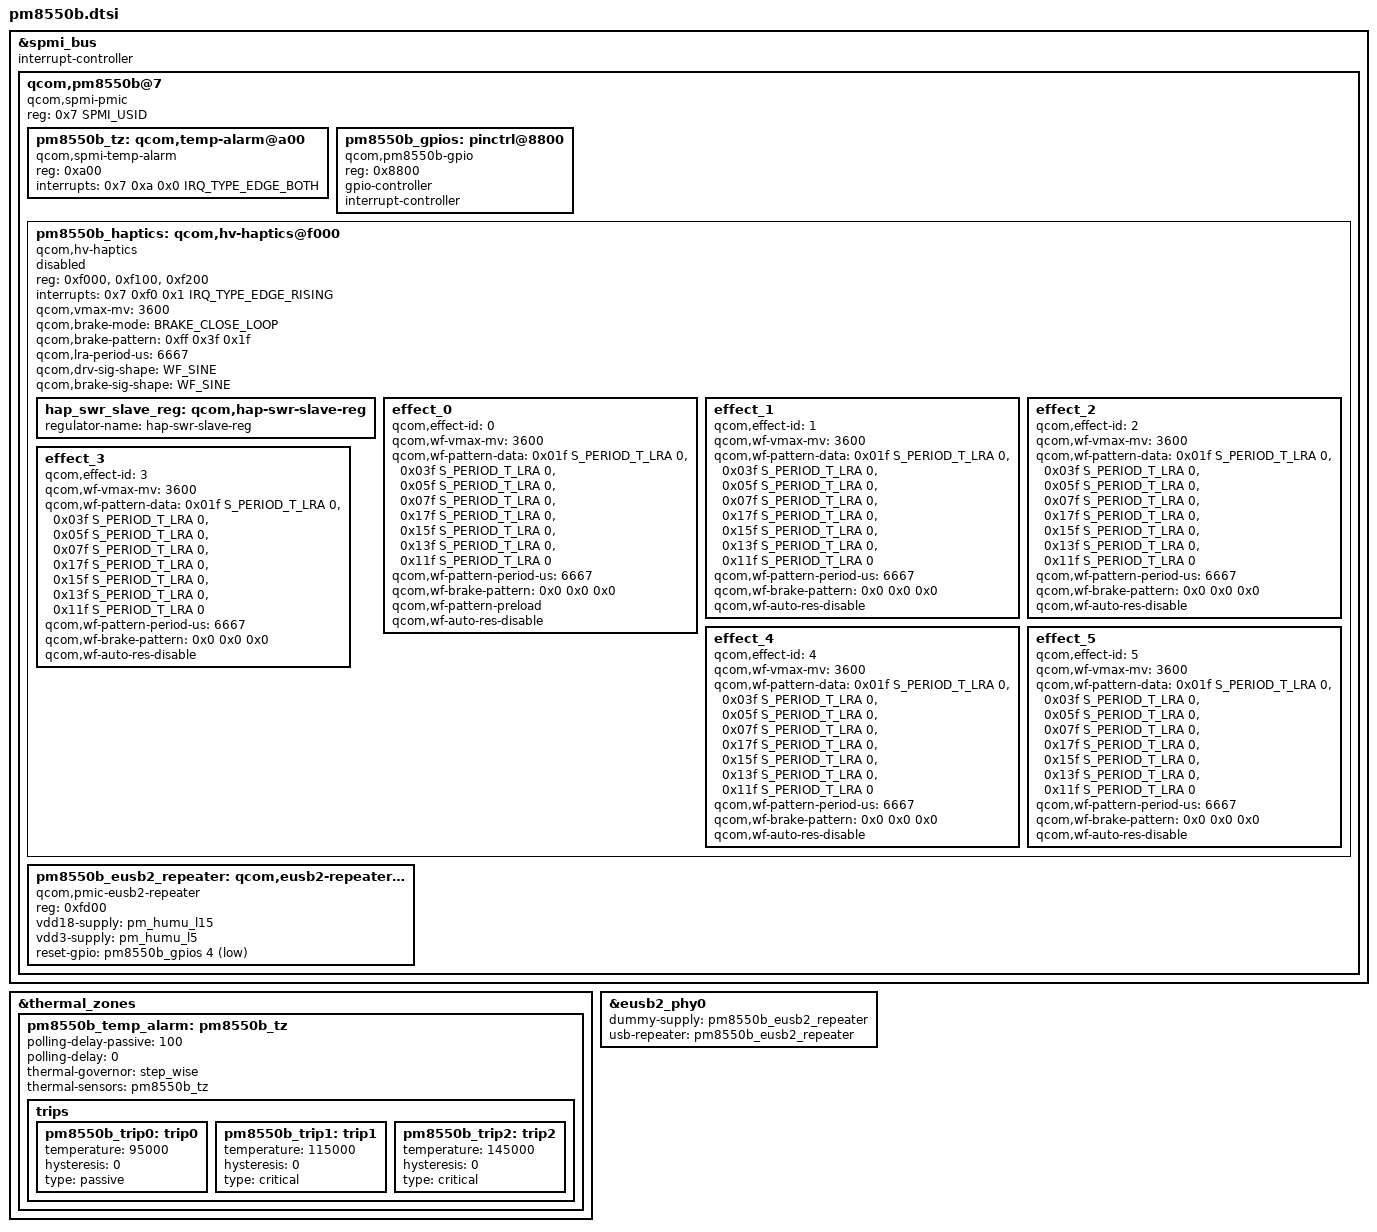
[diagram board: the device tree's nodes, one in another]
#include <dt-bindings/input/qcom,hv-haptics.h>
#include <dt-bindings/interrupt-controller/irq.h>
#include <dt-bindings/spmi/spmi.h>

&spmi_bus {
	#address-cells = <2>;
	#size-cells = <0>;
	interrupt-controller;
	#interrupt-cells = <4>;

	qcom,pm8550b@7 {
		compatible = "qcom,spmi-pmic";
		reg = <0x7 SPMI_USID>;
		#address-cells = <1>;
		#size-cells = <0>;

		pm8550b_tz: qcom,temp-alarm@a00 {
			compatible = "qcom,spmi-temp-alarm";
			reg = <0xa00>;
			interrupts = <0x7 0xa 0x0 IRQ_TYPE_EDGE_BOTH>;
			#thermal-sensor-cells = <0>;
		};

		pm8550b_gpios: pinctrl@8800 {
			compatible = "qcom,pm8550b-gpio";
			reg = <0x8800>;
			gpio-controller;
			#gpio-cells = <2>;
			interrupt-controller;
			#interrupt-cells = <2>;
		};

		pm8550b_haptics: qcom,hv-haptics@f000 {
			compatible = "qcom,hv-haptics";
			reg = <0xf000>, <0xf100>, <0xf200>;
			interrupts = <0x7 0xf0 0x1 IRQ_TYPE_EDGE_RISING>;
			interrupt-names = "fifo-empty";
			qcom,vmax-mv = <3600>;
			qcom,brake-mode = <BRAKE_CLOSE_LOOP>;
			qcom,brake-pattern = /bits/ 8 <0xff 0x3f 0x1f>;
			qcom,lra-period-us = <6667>;
			qcom,drv-sig-shape = <WF_SINE>;
			qcom,brake-sig-shape = <WF_SINE>;
			status = "disabled";

			hap_swr_slave_reg: qcom,hap-swr-slave-reg {
				regulator-name = "hap-swr-slave-reg";
			};

			effect_0 {
				/* CLICK */
				qcom,effect-id = <0>;
				qcom,wf-vmax-mv = <3600>;
				qcom,wf-pattern-data =  <0x01f  S_PERIOD_T_LRA  0>,
							<0x03f  S_PERIOD_T_LRA  0>,
							<0x05f  S_PERIOD_T_LRA  0>,
							<0x07f  S_PERIOD_T_LRA  0>,
							<0x17f  S_PERIOD_T_LRA  0>,
							<0x15f  S_PERIOD_T_LRA  0>,
							<0x13f  S_PERIOD_T_LRA  0>,
							<0x11f  S_PERIOD_T_LRA  0>;
				qcom,wf-pattern-period-us = <6667>;
				qcom,wf-brake-pattern = /bits/ 8 <0x0 0x0 0x0>;
				qcom,wf-pattern-preload;
				qcom,wf-auto-res-disable;
			};

			effect_1 {
				/* DOUBLE_CLICK */
				qcom,effect-id = <1>;
				qcom,wf-vmax-mv = <3600>;
				qcom,wf-pattern-data =  <0x01f  S_PERIOD_T_LRA  0>,
							<0x03f  S_PERIOD_T_LRA  0>,
							<0x05f  S_PERIOD_T_LRA  0>,
							<0x07f  S_PERIOD_T_LRA  0>,
							<0x17f  S_PERIOD_T_LRA  0>,
							<0x15f  S_PERIOD_T_LRA  0>,
							<0x13f  S_PERIOD_T_LRA  0>,
							<0x11f  S_PERIOD_T_LRA  0>;
				qcom,wf-pattern-period-us = <6667>;
				qcom,wf-brake-pattern = /bits/ 8 <0x0 0x0 0x0>;
				qcom,wf-auto-res-disable;
			};

			effect_2 {
				/* TICK */
				qcom,effect-id = <2>;
				qcom,wf-vmax-mv = <3600>;
				qcom,wf-pattern-data =  <0x01f  S_PERIOD_T_LRA  0>,
							<0x03f  S_PERIOD_T_LRA  0>,
							<0x05f  S_PERIOD_T_LRA  0>,
							<0x07f  S_PERIOD_T_LRA  0>,
							<0x17f  S_PERIOD_T_LRA  0>,
							<0x15f  S_PERIOD_T_LRA  0>,
							<0x13f  S_PERIOD_T_LRA  0>,
							<0x11f  S_PERIOD_T_LRA  0>;
				qcom,wf-pattern-period-us = <6667>;
				qcom,wf-brake-pattern = /bits/ 8 <0x0 0x0 0x0>;
				qcom,wf-auto-res-disable;
			};

			effect_3 {
				/* THUD */
				qcom,effect-id = <3>;
				qcom,wf-vmax-mv = <3600>;
				qcom,wf-pattern-data =  <0x01f  S_PERIOD_T_LRA  0>,
							<0x03f  S_PERIOD_T_LRA  0>,
							<0x05f  S_PERIOD_T_LRA  0>,
							<0x07f  S_PERIOD_T_LRA  0>,
							<0x17f  S_PERIOD_T_LRA  0>,
							<0x15f  S_PERIOD_T_LRA  0>,
							<0x13f  S_PERIOD_T_LRA  0>,
							<0x11f  S_PERIOD_T_LRA  0>;
				qcom,wf-pattern-period-us = <6667>;
				qcom,wf-brake-pattern = /bits/ 8 <0x0 0x0 0x0>;
				qcom,wf-auto-res-disable;
			};

			effect_4 {
				/* POP */
				qcom,effect-id = <4>;
				qcom,wf-vmax-mv = <3600>;
				qcom,wf-pattern-data =  <0x01f  S_PERIOD_T_LRA  0>,
							<0x03f  S_PERIOD_T_LRA  0>,
							<0x05f  S_PERIOD_T_LRA  0>,
							<0x07f  S_PERIOD_T_LRA  0>,
							<0x17f  S_PERIOD_T_LRA  0>,
							<0x15f  S_PERIOD_T_LRA  0>,
							<0x13f  S_PERIOD_T_LRA  0>,
							<0x11f  S_PERIOD_T_LRA  0>;
				qcom,wf-pattern-period-us = <6667>;
				qcom,wf-brake-pattern = /bits/ 8 <0x0 0x0 0x0>;
				qcom,wf-auto-res-disable;
			};

			effect_5 {
				/* HEAVY CLICK */
				qcom,effect-id = <5>;
				qcom,wf-vmax-mv = <3600>;
				qcom,wf-pattern-data =  <0x01f  S_PERIOD_T_LRA  0>,
							<0x03f  S_PERIOD_T_LRA  0>,
							<0x05f  S_PERIOD_T_LRA  0>,
							<0x07f  S_PERIOD_T_LRA  0>,
							<0x17f  S_PERIOD_T_LRA  0>,
							<0x15f  S_PERIOD_T_LRA  0>,
							<0x13f  S_PERIOD_T_LRA  0>,
							<0x11f  S_PERIOD_T_LRA  0>;
				qcom,wf-pattern-period-us = <6667>;
				qcom,wf-brake-pattern = /bits/ 8 <0x0 0x0 0x0>;
				qcom,wf-auto-res-disable;
			};
		};

		pm8550b_eusb2_repeater: qcom,eusb2-repeater@fd00 {
			compatible = "qcom,pmic-eusb2-repeater";
			reg = <0xfd00>;
			vdd18-supply = <&pm_humu_l15>;
			vdd3-supply = <&pm_humu_l5>;
			reset-gpio = <&pm8550b_gpios 4 GPIO_ACTIVE_LOW>;
		};
	};
};

&thermal_zones {
	pm8550b_temp_alarm: pm8550b_tz {
		polling-delay-passive = <100>;
		polling-delay = <0>;
		thermal-governor = "step_wise";
		thermal-sensors = <&pm8550b_tz>;

		trips {
			pm8550b_trip0: trip0 {
				temperature = <95000>;
				hysteresis = <0>;
				type = "passive";
			};

			pm8550b_trip1: trip1 {
				temperature = <115000>;
				hysteresis = <0>;
				type = "critical";
			};

			pm8550b_trip2: trip2 {
				temperature = <145000>;
				hysteresis = <0>;
				type = "critical";
			};
		};
	};
};

&eusb2_phy0 {
	dummy-supply = <&pm8550b_eusb2_repeater>;
	usb-repeater = <&pm8550b_eusb2_repeater>;
};
